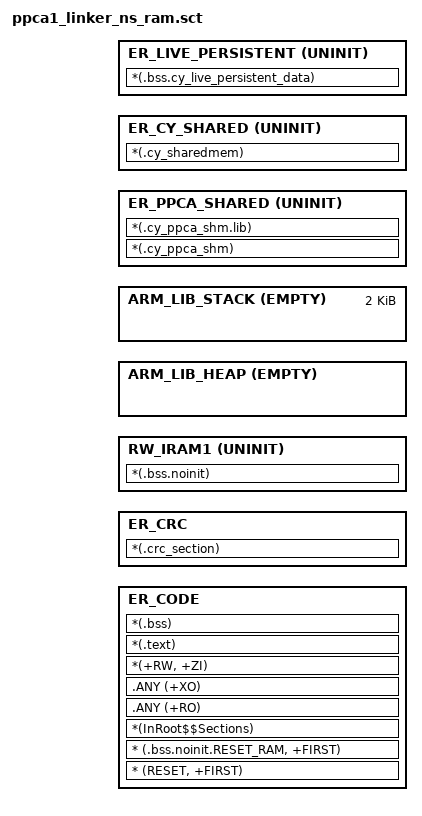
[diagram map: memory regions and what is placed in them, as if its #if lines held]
#! armclang -E --target=arm-arm-none-eabi -x c -mcpu=cortex-m33
; The first line specifies a preprocessor command that the linker invokes
; to pass a scatter file through a C preprocessor.

;*******************************************************************************
;* \file ppca1_linker_ns_ram.sct
;* \version 1.000
;*
;* Linker file for the ARMCC.
;*
;* The main purpose of the linker script is to describe how the sections in the
;* input files should be mapped into the output file, and to control the memory
;* layout of the output file.
;*
;* \note The entry point location is fixed and starts at 0x12000000. The valid
;* application image should be placed there.
;*
;* \note The linker files included with the PDL template projects must be generic
;* and handle all common use cases. Your project may not use every section
;* defined in the linker files. In that case you may see warnings during the
;* build process. In your project, you can simply comment out or remove the
;* relevant code in the linker file.
;*******************************************************************************
;* \copyright
;* Copyright (c) (2024), Cypress Semiconductor Corporation (an Infineon company) or
;* an affiliate of Cypress Semiconductor Corporation.
;* SPDX-License-Identifier: Apache-2.0
;*
;* Licensed under the Apache License, Version 2.0 (the "License");
;* you may not use this file except in compliance with the License.
;* You may obtain a copy of the License at
;*
;*     http://www.apache.org/licenses/LICENSE-2.0
;*
;* Unless required by applicable law or agreed to in writing, software
;* distributed under the License is distributed on an "AS IS" BASIS,
;* WITHOUT WARRANTIES OR CONDITIONS OF ANY KIND, either express or implied.
;* See the License for the specific language governing permissions and
;* limitations under the License.
;******************************************************************************/

; Include the device memory definitions generated by the Device Configurator
#include "../config/GeneratedSource/cymem_armlink_CM33_2.sct"

#ifndef BUILD_NUM
#define BUILD_NUM 0
#endif

#if ((BUILD_NUM % 2) == 0)
#define PPCA1_CODE_START CYMEM_CM33_2_ppca1_code_A_START
#define PPCA1_CODE_SIZE  CYMEM_CM33_2_ppca1_code_A_SIZE
#define PPCA1_CRC_START  CYMEM_CM33_2_ppca1_crc_A_START
#define PPCA1_CRC_SIZE   CYMEM_CM33_2_ppca1_crc_A_SIZE
#else
#define PPCA1_CODE_START CYMEM_CM33_2_ppca1_code_B_START
#define PPCA1_CODE_SIZE  CYMEM_CM33_2_ppca1_code_B_SIZE
#define PPCA1_CRC_START  CYMEM_CM33_2_ppca1_crc_B_START
#define PPCA1_CRC_SIZE   CYMEM_CM33_2_ppca1_crc_B_SIZE
#endif

; The size of the stack section at the end of CM33 SRAM 
#define RAMVECTORS_ALIGNMENT        512
;  2K for stack
#define STACK_SIZE  0x800

; Define symbols for the start and end of the CRC calculation range
#define __crc_start__ PPCA1_CODE_START
#define __crc_end__   PPCA1_CRC_START

; Define the sections
LR_SRAM_CODE PPCA1_CODE_START PPCA1_CODE_SIZE
{
    ER_CODE (PPCA1_CODE_START)
    {
        * (RESET, +FIRST)
        * (.bss.noinit.RESET_RAM, +FIRST)
        *(InRoot$$Sections)
        .ANY (+RO)
        .ANY (+XO)
        *(+RW, +ZI)
        *(.text)
        *(.bss)
    }
}
LR_SRAM_CRC PPCA1_CRC_START PPCA1_CRC_SIZE
{
    ER_CRC PPCA1_CRC_START
    {
        *(.crc_section)
    }
}
LR_SRAM_DATA CYMEM_CM33_2_ppca1_data_START CYMEM_CM33_2_ppca1_data_SIZE
{
    RW_IRAM1 +0 UNINIT
    {
        *(.bss.noinit)
    }

    ARM_LIB_HEAP  +0 EMPTY ((CYMEM_CM33_2_ppca1_data_START+CYMEM_CM33_2_ppca1_data_SIZE)-AlignExpr(ImageLimit(RW_IRAM1), 8)-STACK_SIZE)
    {
    }

    ARM_LIB_STACK (CYMEM_CM33_2_ppca1_data_START+CYMEM_CM33_2_ppca1_data_SIZE) EMPTY -STACK_SIZE
    {
    }

}
LR_SRAM_SHARED CYMEM_CM33_2_ppca_shm_data_START CYMEM_CM33_2_ppca_shm_data_SIZE
{
    ER_PPCA_SHARED CYMEM_CM33_2_ppca_shm_data_START UNINIT
    {
        *(.cy_ppca_shm)
        *(.cy_ppca_shm.lib)
    }

    ER_CY_SHARED AlignExpr(ImageLimit(ER_PPCA_SHARED), 4) UNINIT
    {
        *(.cy_sharedmem)
    }
}

; Live update persistent data - not cleared by .bss/.data init during startup.
; Variables placed in this region survive firmware updates.
; Use __attribute__((section(".cy_live_persistent_data"))) to place data here.
LR_LIVE_PERSISTENT CYMEM_CM33_2_ppca1_live_persistent_data_START CYMEM_CM33_2_ppca1_live_persistent_data_SIZE
{
    ER_LIVE_PERSISTENT CYMEM_CM33_2_ppca1_live_persistent_data_START UNINIT
    {
        *(.bss.cy_live_persistent_data)
    }
}



/* [] END OF FILE */
